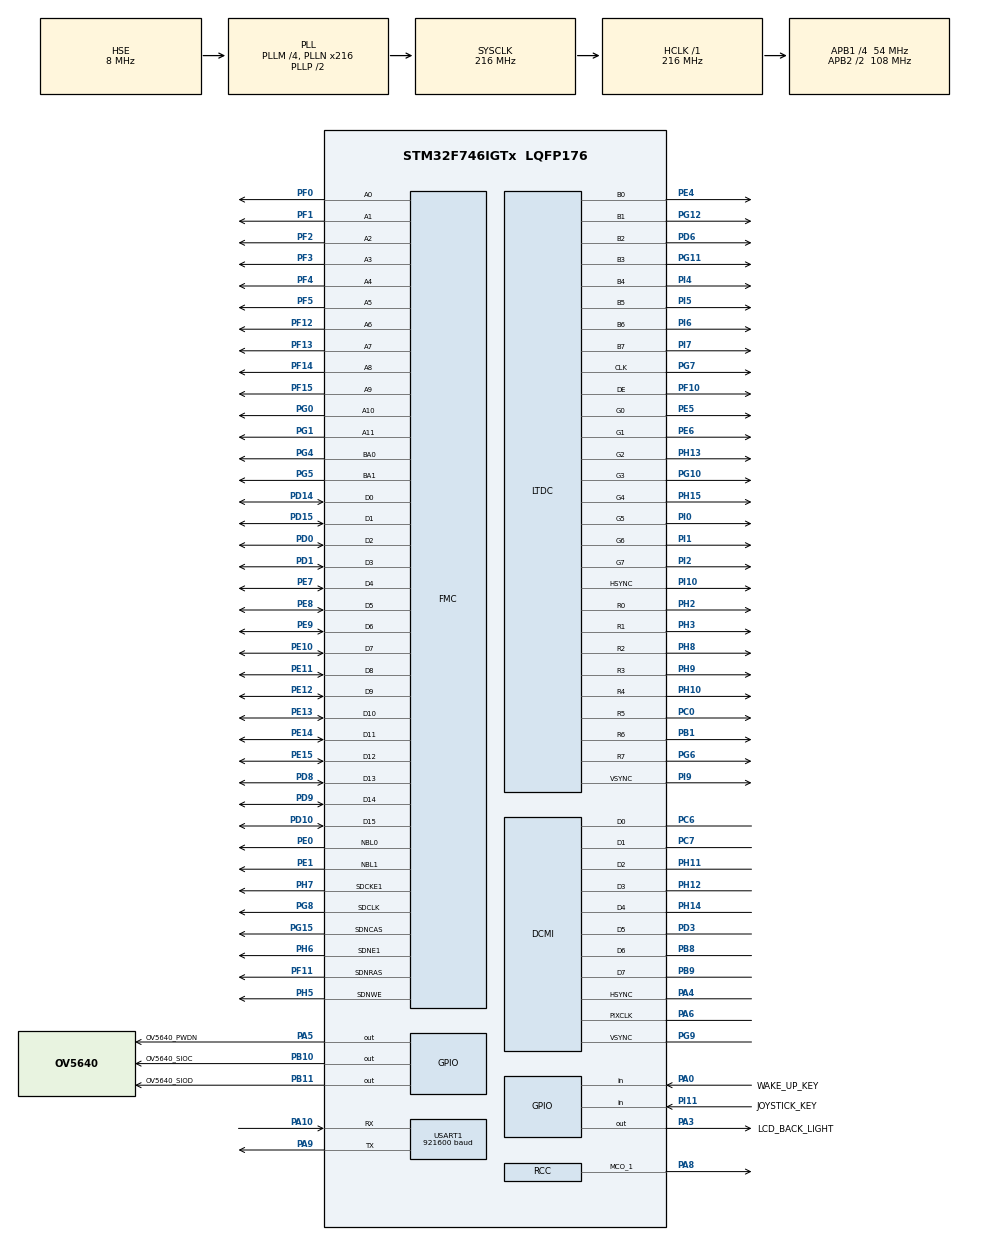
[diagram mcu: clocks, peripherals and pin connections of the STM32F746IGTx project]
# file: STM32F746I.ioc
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CORTEX_M7.CPU_DCache=Enabled
CORTEX_M7.CPU_ICache=Enabled
DCMI.JPEGMode=DCMI_JPEG_ENABLE
DCMI.PCKPolarity=DCMI_PCKPOLARITY_RISING
DMA2D.ColorMode=DMA2D_OUTPUT_RGB565
Dma.DCMI.1.Direction=DMA_PERIPH_TO_MEMORY
Dma.DCMI.1.FIFOMode=DMA_FIFOMODE_ENABLE
Dma.DCMI.1.FIFOThreshold=DMA_FIFO_THRESHOLD_FULL
Dma.DCMI.1.Instance=DMA2_Stream1
Dma.DCMI.1.MemBurst=DMA_MBURST_SINGLE
Dma.DCMI.1.MemDataAlignment=DMA_MDATAALIGN_WORD
Dma.DCMI.1.MemInc=DMA_MINC_ENABLE
Dma.DCMI.1.Mode=DMA_NORMAL
Dma.DCMI.1.PeriphBurst=DMA_PBURST_SINGLE
Dma.DCMI.1.PeriphDataAlignment=DMA_PDATAALIGN_WORD
Dma.DCMI.1.PeriphInc=DMA_PINC_DISABLE
Dma.DCMI.1.Priority=DMA_PRIORITY_VERY_HIGH
Dma.MEMTOMEM.0.Direction=DMA_MEMORY_TO_MEMORY
Dma.MEMTOMEM.0.FIFOMode=DMA_FIFOMODE_ENABLE
Dma.MEMTOMEM.0.FIFOThreshold=DMA_FIFO_THRESHOLD_FULL
Dma.MEMTOMEM.0.Instance=DMA2_Stream0
Dma.MEMTOMEM.0.MemBurst=DMA_MBURST_SINGLE
Dma.MEMTOMEM.0.MemDataAlignment=DMA_MDATAALIGN_WORD
Dma.MEMTOMEM.0.MemInc=DMA_MINC_ENABLE
Dma.MEMTOMEM.0.Mode=DMA_NORMAL
Dma.MEMTOMEM.0.PeriphBurst=DMA_PBURST_SINGLE
Dma.MEMTOMEM.0.PeriphDataAlignment=DMA_PDATAALIGN_WORD
Dma.MEMTOMEM.0.PeriphInc=DMA_PINC_ENABLE
Dma.MEMTOMEM.0.Priority=DMA_PRIORITY_HIGH
Dma.Request0=MEMTOMEM
Dma.Request1=DCMI
FMC.CASLatency1=FMC_SDRAM_CAS_LATENCY_3
FMC.ExitSelfRefreshDelay1=7
FMC.LoadToActiveDelay1=2
FMC.RCDDelay1=2
FMC.RPDelay1=2
FMC.RPDelay2=2
FMC.ReadPipeDelay1=FMC_SDRAM_RPIPE_DELAY_1
FMC.ReadPipeDelay2=FMC_SDRAM_RPIPE_DELAY_1
FMC.RowBitsNumber1=FMC_SDRAM_ROW_BITS_NUM_12
FMC.RowCycleDelay1=6
FMC.RowCycleDelay2=6
FMC.SDClockPeriod1=FMC_SDRAM_CLOCK_PERIOD_2
FMC.SDClockPeriod2=FMC_SDRAM_CLOCK_PERIOD_2
FMC.SelfRefreshTime1=4
FMC.WriteRecoveryTime1=2
LTDC.ActiveH=272
LTDC.ActiveW=480
LTDC.Alpha_L0=0xFF
LTDC.Alpha_L1=0
LTDC.BlendingFactor1_L0=LTDC_BLENDING_FACTOR1_PAxCA
LTDC.BlendingFactor1_L1=LTDC_BLENDING_FACTOR1_PAxCA
LTDC.BlendingFactor2_L0=LTDC_BLENDING_FACTOR2_PAxCA
LTDC.BlendingFactor2_L1=LTDC_BLENDING_FACTOR2_PAxCA
LTDC.FBStartAdress_L0=0xD0000000
LTDC.FBStartAdress_L1=0xD0200000
LTDC.HBP=2
LTDC.HFP=2
LTDC.HSync=41
LTDC.ImageHeight_L0=272
LTDC.ImageHeight_L1=272
LTDC.ImageWidth_L0=480
LTDC.ImageWidth_L1=480
LTDC.Layers=1
LTDC.PixelFormat_L0=LTDC_PIXEL_FORMAT_RGB565
LTDC.PixelFormat_L1=LTDC_PIXEL_FORMAT_RGB565
LTDC.VBP=2
LTDC.VFP=2
LTDC.VSync=10
LTDC.WindowX1_L0=480
LTDC.WindowX1_L1=480
LTDC.WindowY1_L0=272
LTDC.WindowY1_L1=272
Mcu.Family=STM32F7
Mcu.Name=STM32F746IGTx
Mcu.Package=LQFP176
NVIC.DCMI_IRQn=true\:3\:0\:true\:false\:true\:true
NVIC.DMA2_Stream1_IRQn=true\:3\:0\:true\:false\:true\:false
NVIC.PriorityGroup=NVIC_PRIORITYGROUP_4
PA0/WKUP.GPIO_Label=WAKE_UP_KEY
PA0/WKUP.Signal=GPIO_Input
PA10.Mode=Asynchronous
PA10.Signal=USART1_RX
PA13.Mode=Serial_Wire
PA13.Signal=SYS_JTMS-SWDIO
PA14.Mode=Serial_Wire
PA14.Signal=SYS_JTCK-SWCLK
PA3.GPIO_Label=LCD_BACK_LIGHT
PA3.PinState=GPIO_PIN_SET
PA3.Signal=GPIO_Output
PA4.Mode=Slave_8_bits_External_Synchro
PA4.Signal=DCMI_HSYNC
PA5.GPIO_Label=OV5640_PWDN
PA5.PinState=GPIO_PIN_SET
PA5.Signal=GPIO_Output
PA6.Mode=Slave_8_bits_External_Synchro
PA6.Signal=DCMI_PIXCLK
PA8.Mode=Clock-out-1
PA8.Signal=RCC_MCO_1
PA9.Mode=Asynchronous
PA9.Signal=USART1_TX
PB1.GPIO_Speed=GPIO_SPEED_FREQ_VERY_HIGH
PB1.Mode=RGB888
PB1.Signal=LTDC_R6
PB10.GPIO_Label=OV5640_SIOC
PB10.GPIO_ModeDefaultOutputPP=GPIO_MODE_OUTPUT_OD
PB10.GPIO_PuPd=GPIO_PULLUP
PB10.GPIO_Speed=GPIO_SPEED_FREQ_HIGH
PB10.Signal=GPIO_Output
PB11.GPIO_Label=OV5640_SIOD
PB11.GPIO_ModeDefaultOutputPP=GPIO_MODE_OUTPUT_OD
PB11.GPIO_PuPd=GPIO_PULLUP
PB11.GPIO_Speed=GPIO_SPEED_FREQ_HIGH
PB11.Signal=GPIO_Output
PB8.Mode=Slave_8_bits_External_Synchro
PB8.Signal=DCMI_D6
PB9.Mode=Slave_8_bits_External_Synchro
PB9.Signal=DCMI_D7
PC0.GPIO_Speed=GPIO_SPEED_FREQ_VERY_HIGH
PC0.Mode=RGB888
PC0.Signal=LTDC_R5
PC6.Mode=Slave_8_bits_External_Synchro
PC6.Signal=DCMI_D0
PC7.Mode=Slave_8_bits_External_Synchro
PC7.Signal=DCMI_D1
PD0.Signal=FMC_D2_DA2
PD1.Signal=FMC_D3_DA3
PD10.Signal=FMC_D15_DA15
PD14.Signal=FMC_D0_DA0
PD15.Signal=FMC_D1_DA1
PD3.Mode=Slave_8_bits_External_Synchro
PD3.Signal=DCMI_D5
PD6.GPIO_Speed=GPIO_SPEED_FREQ_VERY_HIGH
PD6.Mode=RGB888
PD6.Signal=LTDC_B2
PD8.Signal=FMC_D13_DA13
PD9.Signal=FMC_D14_DA14
PE0.Signal=FMC_NBL0
PE1.Signal=FMC_NBL1
PE10.Signal=FMC_D7_DA7
PE11.Signal=FMC_D8_DA8
PE12.Signal=FMC_D9_DA9
PE13.Signal=FMC_D10_DA10
PE14.Signal=FMC_D11_DA11
PE15.Signal=FMC_D12_DA12
PE4.GPIO_Speed=GPIO_SPEED_FREQ_VERY_HIGH
PE4.Mode=RGB888
PE4.Signal=LTDC_B0
PE5.GPIO_Speed=GPIO_SPEED_FREQ_VERY_HIGH
PE5.Mode=RGB888
PE5.Signal=LTDC_G0
PE6.GPIO_Speed=GPIO_SPEED_FREQ_VERY_HIGH
PE6.Mode=RGB888
PE6.Signal=LTDC_G1
PE7.Signal=FMC_D4_DA4
PE8.Signal=FMC_D5_DA5
PE9.Signal=FMC_D6_DA6
PF0.Signal=FMC_A0
PF1.Signal=FMC_A1
PF10.GPIO_Speed=GPIO_SPEED_FREQ_VERY_HIGH
PF10.Mode=RGB888
PF10.Signal=LTDC_DE
PF11.Signal=FMC_SDNRAS
PF12.Signal=FMC_A6
PF13.Signal=FMC_A7
PF14.Signal=FMC_A8
PF15.Signal=FMC_A9
PF2.Signal=FMC_A2
PF3.Signal=FMC_A3
PF4.Signal=FMC_A4
PF5.Signal=FMC_A5
PG0.Signal=FMC_A10
PG1.Signal=FMC_A11
PG10.GPIO_Speed=GPIO_SPEED_FREQ_VERY_HIGH
PG10.Mode=RGB888
PG10.Signal=LTDC_G3
PG11.GPIO_Speed=GPIO_SPEED_FREQ_VERY_HIGH
PG11.Mode=RGB888
PG11.Signal=LTDC_B3
PG12.GPIO_Speed=GPIO_SPEED_FREQ_VERY_HIGH
PG12.Mode=RGB888
PG12.Signal=LTDC_B1
PG15.Signal=FMC_SDNCAS
PG4.Signal=FMC_A14_BA0
PG5.Signal=FMC_A15_BA1
PG6.GPIO_Speed=GPIO_SPEED_FREQ_VERY_HIGH
PG6.Mode=RGB888
PG6.Signal=LTDC_R7
PG7.GPIO_Speed=GPIO_SPEED_FREQ_VERY_HIGH
PG7.Mode=RGB888
PG7.Signal=LTDC_CLK
PG8.Signal=FMC_SDCLK
PG9.Mode=Slave_8_bits_External_Synchro
PG9.Signal=DCMI_VSYNC
PH0/OSC_IN.Mode=HSE-External-Oscillator
PH0/OSC_IN.Signal=RCC_OSC_IN
PH1/OSC_OUT.Mode=HSE-External-Oscillator
PH1/OSC_OUT.Signal=RCC_OSC_OUT
PH10.GPIO_Speed=GPIO_SPEED_FREQ_VERY_HIGH
PH10.Mode=RGB888
PH10.Signal=LTDC_R4
PH11.Mode=Slave_8_bits_External_Synchro
PH11.Signal=DCMI_D2
PH12.Mode=Slave_8_bits_External_Synchro
PH12.Signal=DCMI_D3
PH13.GPIO_Speed=GPIO_SPEED_FREQ_VERY_HIGH
PH13.Mode=RGB888
PH13.Signal=LTDC_G2
PH14.Mode=Slave_8_bits_External_Synchro
PH14.Signal=DCMI_D4
PH15.GPIO_Speed=GPIO_SPEED_FREQ_VERY_HIGH
PH15.Mode=RGB888
PH15.Signal=LTDC_G4
PH2.GPIO_Speed=GPIO_SPEED_FREQ_VERY_HIGH
PH2.Mode=RGB888
PH2.Signal=LTDC_R0
PH3.GPIO_Speed=GPIO_SPEED_FREQ_VERY_HIGH
PH3.Mode=RGB888
PH3.Signal=LTDC_R1
PH5.Signal=FMC_SDNWE
PH6.Mode=SdramChipSelect2_1
PH6.Signal=FMC_SDNE1
PH7.Mode=SdramChipSelect2_1
PH7.Signal=FMC_SDCKE1
PH8.GPIO_Speed=GPIO_SPEED_FREQ_VERY_HIGH
PH8.Mode=RGB888
PH8.Signal=LTDC_R2
PH9.GPIO_Speed=GPIO_SPEED_FREQ_VERY_HIGH
PH9.Mode=RGB888
PH9.Signal=LTDC_R3
PI0.GPIO_Speed=GPIO_SPEED_FREQ_VERY_HIGH
PI0.Mode=RGB888
PI0.Signal=LTDC_G5
PI1.GPIO_Speed=GPIO_SPEED_FREQ_VERY_HIGH
PI1.Mode=RGB888
PI1.Signal=LTDC_G6
PI10.GPIO_Speed=GPIO_SPEED_FREQ_VERY_HIGH
PI10.Mode=RGB888
PI10.Signal=LTDC_HSYNC
PI11.GPIO_Label=JOYSTICK_KEY
PI11.GPIO_PuPd=GPIO_PULLUP
PI11.Signal=GPIO_Input
PI2.GPIO_Speed=GPIO_SPEED_FREQ_VERY_HIGH
PI2.Mode=RGB888
PI2.Signal=LTDC_G7
PI4.GPIO_Speed=GPIO_SPEED_FREQ_VERY_HIGH
PI4.Mode=RGB888
PI4.Signal=LTDC_B4
PI5.GPIO_Speed=GPIO_SPEED_FREQ_VERY_HIGH
PI5.Mode=RGB888
PI5.Signal=LTDC_B5
PI6.GPIO_Speed=GPIO_SPEED_FREQ_VERY_HIGH
PI6.Mode=RGB888
PI6.Signal=LTDC_B6
PI7.GPIO_Speed=GPIO_SPEED_FREQ_VERY_HIGH
PI7.Mode=RGB888
PI7.Signal=LTDC_B7
PI9.GPIO_Speed=GPIO_SPEED_FREQ_VERY_HIGH
PI9.Mode=RGB888
PI9.Signal=LTDC_VSYNC
ProjectManager.HeapSize=0x200
ProjectManager.StackSize=0x400
ProjectManager.TargetToolchain=MDK-ARM V5
RCC.AHBFreq_Value=216000000
RCC.APB1CLKDivider=RCC_HCLK_DIV4
RCC.APB1Freq_Value=54000000
RCC.APB1TimFreq_Value=108000000
RCC.APB2CLKDivider=RCC_HCLK_DIV2
RCC.APB2Freq_Value=108000000
RCC.APB2TimFreq_Value=216000000
RCC.CortexFreq_Value=216000000
RCC.HCLKFreq_Value=216000000
RCC.HSE_VALUE=8000000
RCC.HSI_VALUE=16000000
RCC.LSE_VALUE=32768
RCC.PLLM=4
RCC.PLLN=216
RCC.PLLSAIN=84
RCC.PLLSAIR=3
RCC.PLLSAIRDiv=RCC_PLLSAIDIVR_4
RCC.PLLSourceVirtual=RCC_PLLSOURCE_HSE
RCC.RCC_MCO1Source=RCC_MCO1SOURCE_HSE
RCC.SYSCLKFreq_VALUE=216000000
RCC.SYSCLKSource=RCC_SYSCLKSOURCE_PLLCLK
RCC.USBFreq_Value=216000000
RCC.VCOOutputFreq_Value=432000000
SH.FMC_A0.0=FMC_A0,12b-sda1
SH.FMC_A1.0=FMC_A1,12b-sda1
SH.FMC_A10.0=FMC_A10,12b-sda1
SH.FMC_A11.0=FMC_A11,12b-sda1
SH.FMC_A14_BA0.0=FMC_BA0,FourSdramBanks1
SH.FMC_A15_BA1.0=FMC_BA1,FourSdramBanks1
SH.FMC_A2.0=FMC_A2,12b-sda1
SH.FMC_A3.0=FMC_A3,12b-sda1
SH.FMC_A4.0=FMC_A4,12b-sda1
SH.FMC_A5.0=FMC_A5,12b-sda1
SH.FMC_A6.0=FMC_A6,12b-sda1
SH.FMC_A7.0=FMC_A7,12b-sda1
SH.FMC_A8.0=FMC_A8,12b-sda1
SH.FMC_A9.0=FMC_A9,12b-sda1
SH.FMC_D0_DA0.0=FMC_D0,sd-16b-d1
SH.FMC_D10_DA10.0=FMC_D10,sd-16b-d1
SH.FMC_D11_DA11.0=FMC_D11,sd-16b-d1
SH.FMC_D12_DA12.0=FMC_D12,sd-16b-d1
SH.FMC_D13_DA13.0=FMC_D13,sd-16b-d1
SH.FMC_D14_DA14.0=FMC_D14,sd-16b-d1
SH.FMC_D15_DA15.0=FMC_D15,sd-16b-d1
SH.FMC_D1_DA1.0=FMC_D1,sd-16b-d1
SH.FMC_D2_DA2.0=FMC_D2,sd-16b-d1
SH.FMC_D3_DA3.0=FMC_D3,sd-16b-d1
SH.FMC_D4_DA4.0=FMC_D4,sd-16b-d1
SH.FMC_D5_DA5.0=FMC_D5,sd-16b-d1
SH.FMC_D6_DA6.0=FMC_D6,sd-16b-d1
SH.FMC_D7_DA7.0=FMC_D7,sd-16b-d1
SH.FMC_D8_DA8.0=FMC_D8,sd-16b-d1
SH.FMC_D9_DA9.0=FMC_D9,sd-16b-d1
SH.FMC_NBL0.0=FMC_NBL0,Sd2ByteEnable1
SH.FMC_NBL1.0=FMC_NBL1,Sd2ByteEnable1
SH.FMC_SDCLK.0=FMC_SDCLK,12b-sda1
SH.FMC_SDNCAS.0=FMC_SDNCAS,12b-sda1
SH.FMC_SDNRAS.0=FMC_SDNRAS,12b-sda1
SH.FMC_SDNWE.0=FMC_SDNWE,12b-sda1
USART1.BaudRate=921600
USART1.VirtualMode-Asynchronous=VM_ASYNC
USART1.WordLength=WORDLENGTH_8B
VP_DMA2D_VS_DMA2D.Mode=DMA2D_Activate
board=STM32F746I

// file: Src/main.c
/**
  ******************************************************************************
  * File Name          : main.c
  * Description        : Main program body
  ******************************************************************************
  ** This notice applies to any and all portions of this file
  * that are not between comment pairs USER CODE BEGIN and
  * USER CODE END. Other portions of this file, whether
  * inserted by the user or by software development tools
  * are owned by their respective copyright owners.
  *
  * COPYRIGHT(c) 2017 STMicroelectronics
  *
  * Redistribution and use in source and binary forms, with or without modification,
  * are permitted provided that the following conditions are met:
  *   1. Redistributions of source code must retain the above copyright notice,
  *      this list of conditions and the following disclaimer.
  *   2. Redistributions in binary form must reproduce the above copyright notice,
  *      this list of conditions and the following disclaimer in the documentation
  *      and/or other materials provided with the distribution.
  *   3. Neither the name of STMicroelectronics nor the names of its contributors
  *      may be used to endorse or promote products derived from this software
  *      without specific prior written permission.
  *
  * THIS SOFTWARE IS PROVIDED BY THE COPYRIGHT HOLDERS AND CONTRIBUTORS "AS IS"
  * AND ANY EXPRESS OR IMPLIED WARRANTIES, INCLUDING, BUT NOT LIMITED TO, THE
  * IMPLIED WARRANTIES OF MERCHANTABILITY AND FITNESS FOR A PARTICULAR PURPOSE ARE
  * DISCLAIMED. IN NO EVENT SHALL THE COPYRIGHT HOLDER OR CONTRIBUTORS BE LIABLE
  * FOR ANY DIRECT, INDIRECT, INCIDENTAL, SPECIAL, EXEMPLARY, OR CONSEQUENTIAL
  * DAMAGES (INCLUDING, BUT NOT LIMITED TO, PROCUREMENT OF SUBSTITUTE GOODS OR
  * SERVICES; LOSS OF USE, DATA, OR PROFITS; OR BUSINESS INTERRUPTION) HOWEVER
  * CAUSED AND ON ANY THEORY OF LIABILITY, WHETHER IN CONTRACT, STRICT LIABILITY,
  * OR TORT (INCLUDING NEGLIGENCE OR OTHERWISE) ARISING IN ANY WAY OUT OF THE USE
  * OF THIS SOFTWARE, EVEN IF ADVISED OF THE POSSIBILITY OF SUCH DAMAGE.
  *
  ******************************************************************************
  */

#include "main.h"
#include "stm32f7xx_hal.h"
#include "dcmi.h"
#include "dma.h"
#include "dma2d.h"
#include "ltdc.h"
#include "usart.h"
#include "gpio.h"
#include "fmc.h"

/* USER CODE BEGIN Includes */

#include "../BSP/stm32746g_sdram.h"
#include "../BSP/stm32746g_LCD.h"
#include "../BSP/ov5640.h"

/* USER CODE END Includes */

/* USER CODE BEGIN PV */
/* Private variables ---------------------------------------------------------*/

/* USER CODE END PV */

void SystemClock_Config(void);

/* USER CODE BEGIN PFP */
/* Private function prototypes -----------------------------------------------*/

/* USER CODE END PFP */

int main(void)
{

  /* Enable I-Cache-------------------------------------------------------------*/
  SCB_EnableICache();

  /* Enable D-Cache-------------------------------------------------------------*/
  SCB_EnableDCache();

  /* MCU Configuration----------------------------------------------------------*/

  /* Reset of all peripherals, Initializes the Flash interface and the Systick. */
  HAL_Init();

  /* Configure the system clock */
  SystemClock_Config();

  /* Initialize all configured peripherals */
  MX_GPIO_Init();
  MX_DMA_Init();
  MX_DMA2D_Init();
  MX_FMC_Init();
  MX_LTDC_Init();
  MX_USART1_UART_Init();
  MX_DCMI_Init();

  /* USER CODE BEGIN 2 */

        BSP_SDRAM_Init();

	BSP_LCD_Init();
        BSP_LCD_SetLayerVisible(1, DISABLE);
        BSP_LCD_SelectLayer(0);
        BSP_LCD_DisplayOn();

        // turn ON the LCD backlight
        HAL_GPIO_WritePin(LCD_BACK_LIGHT_GPIO_Port,LCD_BACK_LIGHT_Pin,GPIO_PIN_SET);
        BSP_LCD_Clear(LCD_COLOR_WHITE);
        BSP_LCD_SetBackColor(LCD_COLOR_WHITE);
        BSP_LCD_SetTextColor(LCD_COLOR_RED);
	BSP_LCD_SetFont(&Font20);

        BSP_LCD_DisplayStringAt(0, 60, (uint8_t *)"Initializing, please wait ...", CENTER_MODE);
        printf("Initializing, please wait ...\r\n");

        while(OV5640_Init())
        {
                printf("OV5640 error, please check !\r\n");
                BSP_LCD_Clear(LCD_COLOR_WHITE);
                HAL_Delay(200);
                BSP_LCD_DisplayStringAt(0, 60, (uint8_t *)"OV5640 error, please check !", CENTER_MODE);
                HAL_Delay(300);
        }
        OV5640_RGB565_Mode();
	OV5640_Light_Mode(0);	   //set auto
	OV5640_Color_Saturation(3); //default
	OV5640_Brightness(4);	//default
	OV5640_Contrast(3);     //default
	OV5640_Sharpness(33);	//set auto

        BSP_LCD_Clear(LCD_COLOR_WHITE);
        BSP_LCD_SetTextColor(LCD_COLOR_BLUE);
        BSP_LCD_DisplayStringAt(0, 60, (uint8_t *)"Waveshare OV5640 Test", CENTER_MODE);
        BSP_LCD_DisplayStringAt(0, 130, (uint8_t *)" WAKE UP:   JPEG", LEFT_MODE);
        BSP_LCD_DisplayStringAt(0, 160, (uint8_t *)" JOYSTICK:  RGB565", LEFT_MODE);

        printf("Waveshare OV5640 Test Start !\r\n");
        printf("WAKE UP:   JPEG \r\n");
        printf("JOYSTICK:   RGB565 \r\n");

  /* USER CODE END 2 */

  /* Infinite loop */
  /* USER CODE BEGIN WHILE */
  while (1)
  {

        if(WAKE_UP_KEY_PRESS)
        {
                HAL_Delay(15);
                if(WAKE_UP_KEY_PRESS)
                {
                        __HAL_RCC_LTDC_CLK_DISABLE();

                        jpeg_test(SVGA_800_600);
                }
                while(WAKE_UP_KEY_PRESS);   // wait until key restore
        }

        if(JOYSTICK_KEY_PRESS)
        {
                HAL_Delay(15);
                if(JOYSTICK_KEY_PRESS)
                {
                        rgb565_test();
                }
                while(JOYSTICK_KEY_PRESS);   // wait until key restore
        }

  /* USER CODE END WHILE */

  }

}

/** System Clock Configuration
*/
void SystemClock_Config(void)
{

  RCC_OscInitTypeDef RCC_OscInitStruct;
  RCC_ClkInitTypeDef RCC_ClkInitStruct;
  RCC_PeriphCLKInitTypeDef PeriphClkInitStruct;

    /**Configure the main internal regulator output voltage
    */
  __HAL_RCC_PWR_CLK_ENABLE();

  __HAL_PWR_VOLTAGESCALING_CONFIG(PWR_REGULATOR_VOLTAGE_SCALE1);

    /**Initializes the CPU, AHB and APB busses clocks
    */
  RCC_OscInitStruct.OscillatorType = RCC_OSCILLATORTYPE_HSE;
  RCC_OscInitStruct.HSEState = RCC_HSE_ON;
  RCC_OscInitStruct.PLL.PLLState = RCC_PLL_ON;
  RCC_OscInitStruct.PLL.PLLSource = RCC_PLLSOURCE_HSE;
  RCC_OscInitStruct.PLL.PLLM = 4;
  RCC_OscInitStruct.PLL.PLLN = 216;
  RCC_OscInitStruct.PLL.PLLP = RCC_PLLP_DIV2;
  RCC_OscInitStruct.PLL.PLLQ = 2;
  if (HAL_RCC_OscConfig(&RCC_OscInitStruct) != HAL_OK)
  {
    _Error_Handler(__FILE__, __LINE__);
  }

    /**Activate the Over-Drive mode
    */
  if (HAL_PWREx_EnableOverDrive() != HAL_OK)
  {
    _Error_Handler(__FILE__, __LINE__);
  }

    /**Initializes the CPU, AHB and APB busses clocks
    */
  RCC_ClkInitStruct.ClockType = RCC_CLOCKTYPE_HCLK|RCC_CLOCKTYPE_SYSCLK
                              |RCC_CLOCKTYPE_PCLK1|RCC_CLOCKTYPE_PCLK2;
  RCC_ClkInitStruct.SYSCLKSource = RCC_SYSCLKSOURCE_PLLCLK;
  RCC_ClkInitStruct.AHBCLKDivider = RCC_SYSCLK_DIV1;
  RCC_ClkInitStruct.APB1CLKDivider = RCC_HCLK_DIV4;
  RCC_ClkInitStruct.APB2CLKDivider = RCC_HCLK_DIV2;

  if (HAL_RCC_ClockConfig(&RCC_ClkInitStruct, FLASH_LATENCY_7) != HAL_OK)
  {
    _Error_Handler(__FILE__, __LINE__);
  }

  PeriphClkInitStruct.PeriphClockSelection = RCC_PERIPHCLK_LTDC|RCC_PERIPHCLK_USART1;
  PeriphClkInitStruct.PLLSAI.PLLSAIN = 84;
  PeriphClkInitStruct.PLLSAI.PLLSAIR = 3;
  PeriphClkInitStruct.PLLSAI.PLLSAIQ = 2;
  PeriphClkInitStruct.PLLSAI.PLLSAIP = RCC_PLLSAIP_DIV2;
  PeriphClkInitStruct.PLLSAIDivQ = 1;
  PeriphClkInitStruct.PLLSAIDivR = RCC_PLLSAIDIVR_4;
  PeriphClkInitStruct.Usart1ClockSelection = RCC_USART1CLKSOURCE_PCLK2;
  if (HAL_RCCEx_PeriphCLKConfig(&PeriphClkInitStruct) != HAL_OK)
  {
    _Error_Handler(__FILE__, __LINE__);
  }

  HAL_RCC_MCOConfig(RCC_MCO1, RCC_MCO1SOURCE_HSE, RCC_MCODIV_1);

    /**Configure the Systick interrupt time
    */
  HAL_SYSTICK_Config(HAL_RCC_GetHCLKFreq()/1000);

    /**Configure the Systick
    */
  HAL_SYSTICK_CLKSourceConfig(SYSTICK_CLKSOURCE_HCLK);

  /* SysTick_IRQn interrupt configuration */
  HAL_NVIC_SetPriority(SysTick_IRQn, 0, 0);
}

void _Error_Handler(char * file, int line)
{
  while(1)
  {
  }
}

/************************ (C) COPYRIGHT STMicroelectronics *****END OF FILE****/
